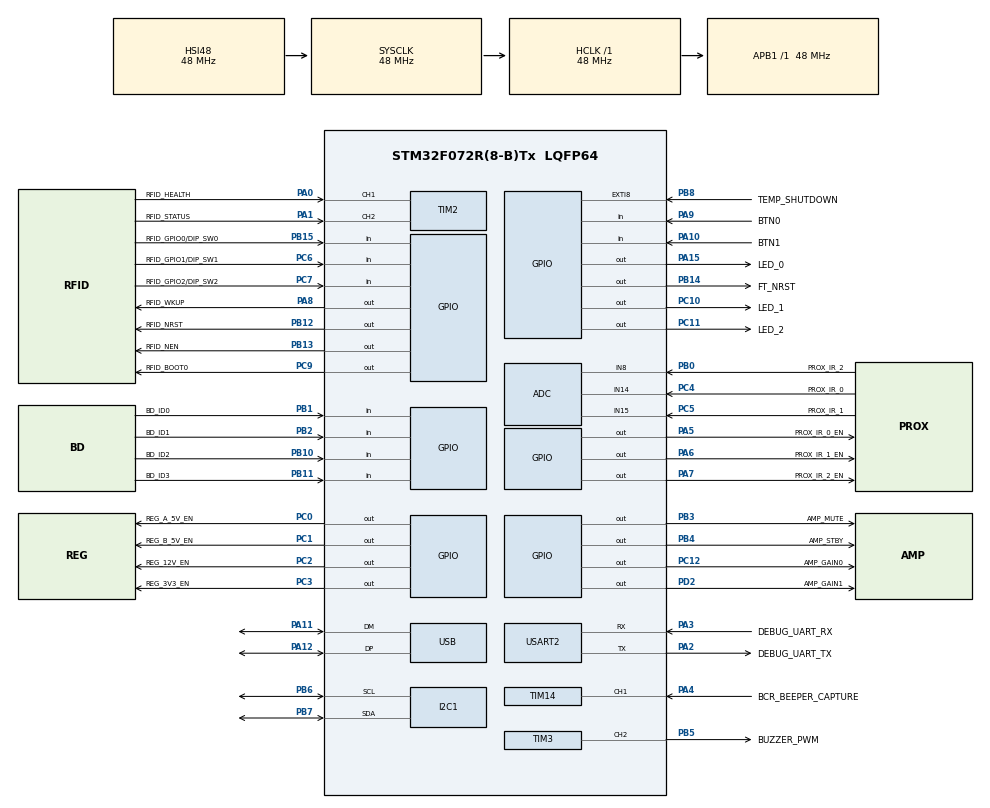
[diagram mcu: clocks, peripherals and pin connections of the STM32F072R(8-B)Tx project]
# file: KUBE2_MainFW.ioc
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I2C1.Timing=0x2000090E
Mcu.Family=STM32F0
Mcu.Name=STM32F072R(8-B)Tx
Mcu.Package=LQFP64
NVIC.USB_IRQn=true\:0\:0\:false
PA0.GPIO_Label=RFID_HEALTH
PA0.Signal=S_TIM2_CH1_ETR
PA1.GPIO_Label=RFID_STATUS
PA1.Signal=S_TIM2_CH2
PA10.GPIO_Label=BTN1
PA10.Signal=GPIO_Input
PA11.Mode=Device
PA11.Signal=USB_DM
PA12.Mode=Device
PA12.Signal=USB_DP
PA13.Mode=Serial-WireDebug
PA13.Signal=SYS_SWDIO
PA14.Mode=Serial-WireDebug
PA14.Signal=SYS_SWCLK
PA15.GPIO_Label=LED_0
PA15.Signal=GPIO_Output
PA2.GPIO_Label=DEBUG_UART_TX
PA2.Mode=Asynchronous
PA2.Signal=USART2_TX
PA3.GPIO_Label=DEBUG_UART_RX
PA3.Mode=Asynchronous
PA3.Signal=USART2_RX
PA4.GPIO_Label=BCR_BEEPER_CAPTURE
PA4.Signal=S_TIM14_CH1
PA5.GPIO_Label=PROX_IR_0_EN
PA5.Signal=GPIO_Output
PA6.GPIO_Label=PROX_IR_1_EN
PA6.Signal=GPIO_Output
PA7.GPIO_Label=PROX_IR_2_EN
PA7.Signal=GPIO_Output
PA8.GPIO_Label=RFID_WKUP
PA8.Signal=GPIO_Output
PA9.GPIO_Label=BTN0
PA9.Signal=GPIO_Input
PB0.GPIO_Label=PROX_IR_2
PB0.Mode=IN8
PB0.Signal=ADC_IN8
PB1.GPIO_Label=BD_ID0
PB1.Signal=GPIO_Input
PB10.GPIO_Label=BD_ID2
PB10.Signal=GPIO_Input
PB11.GPIO_Label=BD_ID3
PB11.Signal=GPIO_Input
PB12.GPIO_Label=RFID_NRST
PB12.Signal=GPIO_Output
PB13.GPIO_Label=RFID_NEN
PB13.Signal=GPIO_Output
PB14.GPIO_Label=FT_NRST
PB14.Signal=GPIO_Output
PB15.GPIO_Label=RFID_GPIO0/DIP_SW0
PB15.Signal=GPIO_Input
PB2.GPIO_Label=BD_ID1
PB2.Signal=GPIO_Input
PB3.GPIO_Label=AMP_MUTE
PB3.Signal=GPIO_Output
PB4.GPIO_Label=AMP_STBY
PB4.Signal=GPIO_Output
PB5.GPIO_Label=BUZZER_PWM
PB5.Signal=S_TIM3_CH2
PB6.Mode=I2C
PB6.Signal=I2C1_SCL
PB7.Mode=I2C
PB7.Signal=I2C1_SDA
PB8.GPIO_Label=TEMP_SHUTDOWN
PB8.Signal=GPXTI8
PC0.GPIO_Label=REG_A_5V_EN
PC0.Signal=GPIO_Output
PC1.GPIO_Label=REG_B_5V_EN
PC1.Signal=GPIO_Output
PC10.GPIO_Label=LED_1
PC10.Signal=GPIO_Output
PC11.GPIO_Label=LED_2
PC11.Signal=GPIO_Output
PC12.GPIO_Label=AMP_GAIN0
PC12.Signal=GPIO_Output
PC14-OSC32_IN.GPIO_Label=OSC32_IN
PC14-OSC32_IN.Mode=LSE-External-Oscillator
PC14-OSC32_IN.Signal=RCC_OSC32_IN
PC15-OSC32_OUT.GPIO_Label=OSC32_OUT
PC15-OSC32_OUT.Mode=LSE-External-Oscillator
PC15-OSC32_OUT.Signal=RCC_OSC32_OUT
PC2.GPIO_Label=REG_12V_EN
PC2.Signal=GPIO_Output
PC3.GPIO_Label=REG_3V3_EN
PC3.Signal=GPIO_Output
PC4.GPIO_Label=PROX_IR_0
PC4.Mode=IN14
PC4.Signal=ADC_IN14
PC5.GPIO_Label=PROX_IR_1
PC5.Mode=IN15
PC5.Signal=ADC_IN15
PC6.GPIO_Label=RFID_GPIO1/DIP_SW1
PC6.Signal=GPIO_Input
PC7.GPIO_Label=RFID_GPIO2/DIP_SW2
PC7.Signal=GPIO_Input
PC9.GPIO_Label=RFID_BOOT0
PC9.Signal=GPIO_Output
PD2.GPIO_Label=AMP_GAIN1
PD2.Signal=GPIO_Output
PF0-OSC_IN.GPIO_Label=OSC_IN
PF0-OSC_IN.Mode=HSE-External-Oscillator
PF0-OSC_IN.Signal=RCC_OSC_IN
PF1-OSC_OUT.GPIO_Label=OSC_OUT
PF1-OSC_OUT.Mode=HSE-External-Oscillator
PF1-OSC_OUT.Signal=RCC_OSC_OUT
ProjectManager.TargetToolchain=MDK-ARM V5
RCC.AHBFreq_Value=48000000
RCC.APB1Freq_Value=48000000
RCC.APB1TimFreq_Value=48000000
RCC.HCLKFreq_Value=48000000
RCC.PLLSourceVirtual=RCC_PLLSOURCE_HSE
RCC.SYSCLKFreq_VALUE=48000000
RCC.SYSCLKSource=RCC_SYSCLKSOURCE_HSI48
SH.S_TIM14_CH1.0=TIM14_CH1,Input_Capture1_from_TI1
SH.S_TIM2_CH1_ETR.0=TIM2_CH1,Input_Capture1_from_TI1
SH.S_TIM2_CH2.0=TIM2_CH2,Input_Capture2_from_TI2
SH.S_TIM3_CH2.0=TIM3_CH2,PWM Generation2 CH2
TIM2.Channel-Input_Capture2_from_TI2=TIM_CHANNEL_2
TIM3.Channel-PWM\ Generation2\ CH2=TIM_CHANNEL_2
USB_DEVICE.USBD_HandleTypeDef=hUsbDeviceFS
USB_DEVICE.VirtualMode=Hid
USB_DEVICE.VirtualModeFS=Hid_FS
VP_TIM14_VS_ClockSourceINT.Mode=Enable_Timer
VP_USB_DEVICE_VS_USB_DEVICE_HID_FS.Mode=HID_FS
board=KUBE2_MainFW

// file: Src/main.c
/**
  ******************************************************************************
  * File Name          : main.c
  * Description        : Main program body
  ******************************************************************************
  *
  * COPYRIGHT(c) 2016 STMicroelectronics
  *
  * Redistribution and use in source and binary forms, with or without modification,
  * are permitted provided that the following conditions are met:
  *   1. Redistributions of source code must retain the above copyright notice,
  *      this list of conditions and the following disclaimer.
  *   2. Redistributions in binary form must reproduce the above copyright notice,
  *      this list of conditions and the following disclaimer in the documentation
  *      and/or other materials provided with the distribution.
  *   3. Neither the name of STMicroelectronics nor the names of its contributors
  *      may be used to endorse or promote products derived from this software
  *      without specific prior written permission.
  *
  * THIS SOFTWARE IS PROVIDED BY THE COPYRIGHT HOLDERS AND CONTRIBUTORS "AS IS"
  * AND ANY EXPRESS OR IMPLIED WARRANTIES, INCLUDING, BUT NOT LIMITED TO, THE
  * IMPLIED WARRANTIES OF MERCHANTABILITY AND FITNESS FOR A PARTICULAR PURPOSE ARE
  * DISCLAIMED. IN NO EVENT SHALL THE COPYRIGHT HOLDER OR CONTRIBUTORS BE LIABLE
  * FOR ANY DIRECT, INDIRECT, INCIDENTAL, SPECIAL, EXEMPLARY, OR CONSEQUENTIAL
  * DAMAGES (INCLUDING, BUT NOT LIMITED TO, PROCUREMENT OF SUBSTITUTE GOODS OR
  * SERVICES; LOSS OF USE, DATA, OR PROFITS; OR BUSINESS INTERRUPTION) HOWEVER
  * CAUSED AND ON ANY THEORY OF LIABILITY, WHETHER IN CONTRACT, STRICT LIABILITY,
  * OR TORT (INCLUDING NEGLIGENCE OR OTHERWISE) ARISING IN ANY WAY OUT OF THE USE
  * OF THIS SOFTWARE, EVEN IF ADVISED OF THE POSSIBILITY OF SUCH DAMAGE.
  *
  ******************************************************************************
  */
#include "stm32f0xx_hal.h"
#include "adc.h"
#include "i2c.h"
#include "tim.h"
#include "usart.h"
#include "usb_device.h"
#include "gpio.h"
#include "system.h"
#include "led.h"
#include "btn.h"
#include "barcode.h"
#include "rfid.h"

/* USER CODE BEGIN PV */
/* Private variables ---------------------------------------------------------*/

/* USER CODE END PV */

void SystemClock_Config(void);

/* USER CODE BEGIN PFP */
/* Private function prototypes -----------------------------------------------*/

/* USER CODE END PFP */

int main(void)
{
//    GPIO_InitTypeDef GPIO_InitStruct;
	long i = 0;

  /* MCU Configuration----------------------------------------------------------*/

  /* Reset of all peripherals, Initializes the Flash interface and the Systick. */
  HAL_Init();

  /* Configure the system clock */
  SystemClock_Config();

  /* Initialize all configured peripherals */
  MX_GPIO_Init();
  MX_ADC_Init();
  MX_I2C1_Init();
  MX_TIM2_Init();
  MX_TIM3_Init();
  MX_TIM14_Init();
  MX_USART2_UART_Init();
  MX_USB_DEVICE_Init();

//	GPIO_InitStruct.Pin = RFID_GPIO1_DIP_SW1_Pin;
//  GPIO_InitStruct.Mode = GPIO_MODE_OUTPUT_PP;
//  GPIO_InitStruct.Pull = GPIO_NOPULL;
//  GPIO_InitStruct.Speed = GPIO_SPEED_LOW;
//  HAL_GPIO_Init(GPIOC, &GPIO_InitStruct);
//
//	GPIO_InitStruct.Pin = RFID_GPIO2_DIP_SW2_Pin;
//  GPIO_InitStruct.Mode = GPIO_MODE_OUTPUT_PP;
//  GPIO_InitStruct.Pull = GPIO_NOPULL;
//  GPIO_InitStruct.Speed = GPIO_SPEED_LOW;
//  HAL_GPIO_Init(GPIOC, &GPIO_InitStruct);

  /* Infinite loop */
  while (1)
  {

  /* USER CODE BEGIN 3 */
		if(btn_Read(BTN1) == GPIO_PIN_RESET)
		{
			rfid_FT_UartBridge_Reset();
			//HAL_GPIO_WritePin(RFID_GPIO1_DIP_SW1_GPIO_Port, RFID_GPIO1_DIP_SW1_Pin, GPIO_PIN_SET);
			led_Turn_On(LED0);
			for(i = 0; i < 1000000; i++);
			//HAL_GPIO_WritePin(RFID_GPIO1_DIP_SW1_GPIO_Port, RFID_GPIO1_DIP_SW1_Pin, GPIO_PIN_RESET);
			led_Turn_Off(LED0);
			for(i = 0; i < 1000000; i++);
		}
		else
		{
			rfid_Turn_On();
			//HAL_GPIO_WritePin(RFID_GPIO2_DIP_SW2_GPIO_Port, RFID_GPIO2_DIP_SW2_Pin, GPIO_PIN_SET);
			led_Turn_On(LED2);
			for(i = 0; i < 1000000; i++);
			//HAL_GPIO_WritePin(RFID_GPIO2_DIP_SW2_GPIO_Port, RFID_GPIO2_DIP_SW2_Pin, GPIO_PIN_RESET);
			led_Turn_Off(LED2);
			for(i = 0; i < 1000000; i++);
		}

  }
  /* USER CODE END 3 */

}

/** System Clock Configuration
*/
void SystemClock_Config(void)
{

  RCC_OscInitTypeDef RCC_OscInitStruct;
  RCC_ClkInitTypeDef RCC_ClkInitStruct;
  RCC_PeriphCLKInitTypeDef PeriphClkInit;

  RCC_OscInitStruct.OscillatorType = RCC_OSCILLATORTYPE_HSI|RCC_OSCILLATORTYPE_HSI14
                              |RCC_OSCILLATORTYPE_HSI48;
  RCC_OscInitStruct.HSIState = RCC_HSI_ON;
  RCC_OscInitStruct.HSI48State = RCC_HSI48_ON;
  RCC_OscInitStruct.HSI14State = RCC_HSI14_ON;
  RCC_OscInitStruct.HSICalibrationValue = 16;
  RCC_OscInitStruct.HSI14CalibrationValue = 16;
  RCC_OscInitStruct.PLL.PLLState = RCC_PLL_NONE;
  HAL_RCC_OscConfig(&RCC_OscInitStruct);

  RCC_ClkInitStruct.ClockType = RCC_CLOCKTYPE_SYSCLK;
  RCC_ClkInitStruct.SYSCLKSource = RCC_SYSCLKSOURCE_HSI48;
  RCC_ClkInitStruct.AHBCLKDivider = RCC_SYSCLK_DIV1;
  RCC_ClkInitStruct.APB1CLKDivider = RCC_HCLK_DIV1;
  HAL_RCC_ClockConfig(&RCC_ClkInitStruct, FLASH_LATENCY_1);

  PeriphClkInit.PeriphClockSelection = RCC_PERIPHCLK_USB|RCC_PERIPHCLK_USART2
                              |RCC_PERIPHCLK_I2C1;
  PeriphClkInit.Usart2ClockSelection = RCC_USART2CLKSOURCE_PCLK1;
  PeriphClkInit.I2c1ClockSelection = RCC_I2C1CLKSOURCE_HSI;
  PeriphClkInit.UsbClockSelection = RCC_USBCLKSOURCE_HSI48;
  HAL_RCCEx_PeriphCLKConfig(&PeriphClkInit);

  HAL_RCC_MCOConfig(RCC_MCO, RCC_MCOSOURCE_SYSCLK, RCC_MCO_DIV1);

  HAL_SYSTICK_Config(HAL_RCC_GetHCLKFreq()/1000);

  HAL_SYSTICK_CLKSourceConfig(SYSTICK_CLKSOURCE_HCLK);

  /* SysTick_IRQn interrupt configuration */
  HAL_NVIC_SetPriority(SysTick_IRQn, 0, 0);
}

/************************ (C) COPYRIGHT STMicroelectronics *****END OF FILE****/
